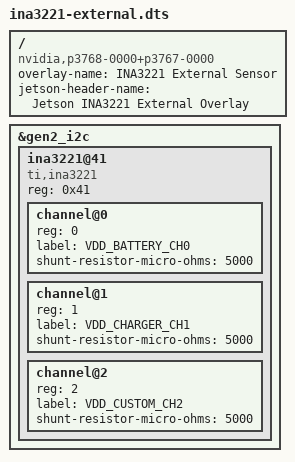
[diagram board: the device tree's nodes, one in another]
/dts-v1/;
/plugin/;

/ {
	overlay-name = "INA3221 External Sensor";
	jetson-header-name = "Jetson INA3221 External Overlay";
	compatible = "nvidia,p3768-0000+p3767-0000", "nvidia,p3768-0000+p3767-0001", "nvidia,p3768-0000+p3767-0003", "nvidia,p3768-0000+p3767-0004", "nvidia,p3768-0000+p3767-0005", "nvidia,p3509-0000+p3767-0000", "nvidia,p3509-0000+p3767-0001", "nvidia,p3509-0000+p3767-0003", "nvidia,p3509-0000+p3767-0004", "nvidia,p3509-0000+p3767-0005";

	fragment@0 {
		target = <&gen2_i2c>;
		__overlay__ {
			ina3221@41 {
				compatible = "ti,ina3221";
				reg = <0x41>;
				#address-cells = <1>;
				#size-cells = <0>;
				#io-channel-cells = <1>;
				status = "okay";

				channel@0 {
					reg = <0>;
					label = "VDD_BATTERY_CH0";
					shunt-resistor-micro-ohms = <5000>;
				};

				channel@1 {
					reg = <1>;
					label = "VDD_CHARGER_CH1";
					shunt-resistor-micro-ohms = <5000>;
				};

				channel@2 {
					reg = <2>;
					label = "VDD_CUSTOM_CH2";
					shunt-resistor-micro-ohms = <5000>;
				};
			};
		};
	};

	__fixups__ {
		gen2_i2c = "/fragment@0:target:0";
	};
};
